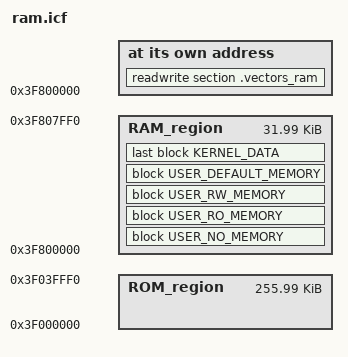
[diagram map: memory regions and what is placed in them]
/*###ICF### Section handled by ICF editor, don't touch! ****/
/*-Editor annotation file-*/
/* IcfEditorFile="$TOOLKIT_DIR$\config\ide\IcfEditor\cortex_v1_0.xml" */
/*-Specials-*/
define symbol __ICFEDIT_intvec_start__ = 0x3f000000;
/*-Memory Regions-*/
define symbol __ICFEDIT_region_ROM_start__   = 0x3f000000; /* physically On Chip SRAM */
define symbol __ICFEDIT_region_ROM_end__     = 0x3f03fff0;
define symbol __ICFEDIT_region_RAM_start__   = 0x3f800000; /* TCMH memory */
define symbol __ICFEDIT_region_RAM_end__     = 0x3f807ff0;
define symbol __ICFEDIT_region_RAM2_start__   = 0x1f800000; /* TCML memory extends the memory pool in _bsp_enable_card */
define symbol __ICFEDIT_region_RAM2_end__     = 0x1f807ff0;

/*-Sizes-*/
define symbol __ICFEDIT_size_cstack__   = 0x400;
define symbol __ICFEDIT_size_heap__     = 0x200;
/**** End of ICF editor section. ###ICF###*/

define exported symbol __VECTOR_TABLE_ROM_START = 0x3f000000;
define exported symbol __VECTOR_TABLE_RAM_START = __ICFEDIT_region_RAM_start__;

define exported symbol __DEFAULT_PROCESSOR_NUMBER       = 1;
/* define exported symbol __DEFAULT_INTERRUPT_STACK_SIZE = 3000; //used BSP_DEFAULT_INTERRUPT_STACK_SIZE instead */
define exported symbol __SHARED_RAM_START               = 0x3f040000;
define exported symbol __SHARED_RAM_END                 = 0x3f04fff0;
define exported symbol __SRAM_POOL_START                = __ICFEDIT_region_RAM_start__;
define exported symbol __SRAM_POOL_END                  = __ICFEDIT_region_RAM_end__;
define exported symbol __UNCACHED_DATA_START            = __ICFEDIT_region_RAM_start__;
define exported symbol __UNCACHED_DATA_END              = __ICFEDIT_region_RAM_end__;

/* mem_init writes a storeblock_struct at the end of kernel data, max size 32 bytes, so use 0x100 offset */
define exported symbol __BOOT_STACK_ADDRESS = __ICFEDIT_region_RAM2_end__ - 0x100;

define exported symbol __KERNEL_DATA_END = __ICFEDIT_region_RAM_end__;

define memory mem with size = 4G;
define region ROM_region   = mem:[from __ICFEDIT_region_ROM_start__   to __ICFEDIT_region_ROM_end__];
define region RAM_region   = mem:[from __ICFEDIT_region_RAM_start__   to __ICFEDIT_region_RAM_end__];

define block KERNEL_DATA with alignment = 8 { section .kernel_data };

define block USER_RW_MEMORY with alignment = 32 { section .rwuser };
define block USER_RO_MEMORY with alignment = 32 { section .rouser };
define block USER_NO_MEMORY with alignment = 32 { section .nouser };

define block USER_DEFAULT_MEMORY with alignment = 32 { readwrite };

initialize by copy { readwrite };
do not initialize  { section .noinit };
do not initialize  { section .kernel_data };


place in ROM_region   { first block head { readonly section .intvec }, readonly };
place at address mem:__ICFEDIT_region_RAM_start__ { readwrite section .vectors_ram };

/* each block/segment must be in one line (association to region) because I need kernel data start after other datas */
place in RAM_region   { block USER_NO_MEMORY, block USER_RO_MEMORY, block USER_RW_MEMORY, block USER_DEFAULT_MEMORY, last block KERNEL_DATA };

